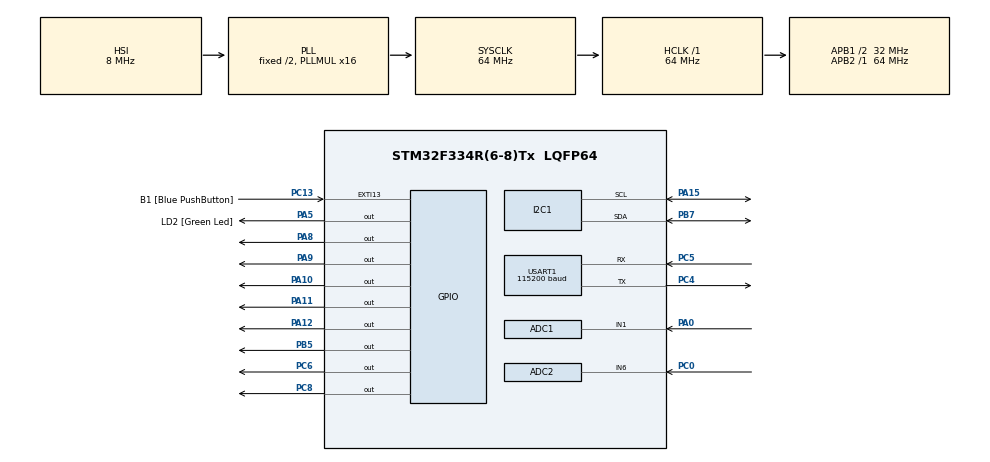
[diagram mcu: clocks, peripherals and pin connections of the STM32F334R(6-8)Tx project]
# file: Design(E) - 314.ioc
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ADC1.Channel-0\#ChannelRegularConversion=ADC_CHANNEL_1
ADC1.NbrOfConversionFlag=1
ADC1.Offset-0\#ChannelRegularConversion=0
ADC1.OffsetNumber-0\#ChannelRegularConversion=ADC_OFFSET_NONE
ADC1.Rank-0\#ChannelRegularConversion=1
ADC1.SamplingTime-0\#ChannelRegularConversion=ADC_SAMPLETIME_1CYCLE_5
ADC1.SubFamily=STM32F334x8
ADC1.master=1
ADC2.Channel-10\#ChannelRegularConversion=ADC_CHANNEL_6
ADC2.NbrOfConversionFlag=1
ADC2.Offset-10\#ChannelRegularConversion=0
ADC2.OffsetNumber-10\#ChannelRegularConversion=ADC_OFFSET_NONE
ADC2.Rank-10\#ChannelRegularConversion=1
ADC2.SamplingTime-10\#ChannelRegularConversion=ADC_SAMPLETIME_1CYCLE_5
ADC2.SubFamily=STM32F334x8
Mcu.Family=STM32F3
Mcu.Name=STM32F334R(6-8)Tx
Mcu.Package=LQFP64
NVIC.ADC1_2_IRQn=true\:0\:0\:false\:false\:true\:true\:true
NVIC.PriorityGroup=NVIC_PRIORITYGROUP_0
NVIC.USART1_IRQn=true\:0\:0\:false\:false\:true\:true\:true
PA0.Signal=SharedAnalog_PA0
PA10.Signal=GPIO_Output
PA11.Signal=GPIO_Output
PA12.Signal=GPIO_Output
PA13.GPIO_Label=TMS
PA13.Mode=Serial_Wire
PA13.Signal=SYS_JTMS-SWDIO
PA14.GPIO_Label=TCK
PA14.Mode=Serial_Wire
PA14.Signal=SYS_JTCK-SWCLK
PA15.Mode=I2C
PA15.Signal=I2C1_SCL
PA5.GPIO_Label=LD2 [Green Led]
PA5.Signal=GPIO_Output
PA8.Signal=GPIO_Output
PA9.Signal=GPIO_Output
PB3.GPIO_Label=SWO
PB3.Signal=SYS_JTDO-TRACESWO
PB5.Signal=GPIO_Output
PB7.Mode=I2C
PB7.Signal=I2C1_SDA
PC0.Signal=SharedAnalog_PC0
PC13.GPIO_Label=B1 [Blue PushButton]
PC13.GPIO_ModeDefaultEXTI=GPIO_MODE_IT_FALLING
PC13.Signal=GPXTI13
PC14\ /\ OSC32_IN.Mode=LSE-External-Oscillator
PC14\ /\ OSC32_IN.Signal=RCC_OSC32_IN
PC15\ /\ OSC32_OUT.GPIO_Label=RCC_OSC32_OUT
PC15\ /\ OSC32_OUT.Mode=LSE-External-Oscillator
PC15\ /\ OSC32_OUT.Signal=RCC_OSC32_OUT
PC4.Mode=Asynchronous
PC4.Signal=USART1_TX
PC5.Mode=Asynchronous
PC5.Signal=USART1_RX
PC6.Signal=GPIO_Output
PC8.Signal=GPIO_Output
PF0\ /\ OSC_IN.Mode=HSE-External-Clock-Source
PF0\ /\ OSC_IN.Signal=RCC_OSC_IN
PF1\ /\ OSC_OUT.Signal=RCC_OSC_OUT
ProjectManager.HeapSize=0x200
ProjectManager.StackSize=0x400
ProjectManager.TargetToolchain=TrueSTUDIO
RCC.AHBFreq_Value=64000000
RCC.APB1CLKDivider=RCC_HCLK_DIV2
RCC.APB1Freq_Value=32000000
RCC.APB1TimFreq_Value=64000000
RCC.APB2Freq_Value=64000000
RCC.APB2TimFreq_Value=64000000
RCC.CortexFreq_Value=64000000
RCC.FLatency-AdvancedSettings=FLASH_LATENCY_2
RCC.HCLKFreq_Value=64000000
RCC.HSE_VALUE=8000000
RCC.HSI_VALUE=8000000
RCC.PLLMUL=RCC_PLL_MUL16
RCC.SYSCLKFreq_VALUE=64000000
RCC.SYSCLKSourceVirtual=RCC_SYSCLKSOURCE_PLLCLK
SH.SharedAnalog_PA0.0=GPIO_Analog
SH.SharedAnalog_PA0.1=ADC1_IN1,IN1-Single-Ended
SH.SharedAnalog_PC0.0=GPIO_Analog
SH.SharedAnalog_PC0.1=ADC2_IN6,IN6-Single-Ended
USART1.BaudRate=115200
USART1.VirtualMode-Asynchronous=VM_ASYNC
board=NUCLEO-F334R8

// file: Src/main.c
/* USER CODE BEGIN Header */
/**
  ******************************************************************************
  * @file           : main.c
  * @brief          : Main program body
  ******************************************************************************
  ** This notice applies to any and all portions of this file
  * that are not between comment pairs USER CODE BEGIN and
  * USER CODE END. Other portions of this file, whether
  * inserted by the user or by software development tools
  * are owned by their respective copyright owners.
  *
  * COPYRIGHT(c) 2019 STMicroelectronics
  *
  * Redistribution and use in source and binary forms, with or without modification,
  * are permitted provided that the following conditions are met:
  *   1. Redistributions of source code must retain the above copyright notice,
  *      this list of conditions and the following disclaimer.
  *   2. Redistributions in binary form must reproduce the above copyright notice,
  *      this list of conditions and the following disclaimer in the documentation
  *      and/or other materials provided with the distribution.
  *   3. Neither the name of STMicroelectronics nor the names of its contributors
  *      may be used to endorse or promote products derived from this software
  *      without specific prior written permission.
  *
  * THIS SOFTWARE IS PROVIDED BY THE COPYRIGHT HOLDERS AND CONTRIBUTORS "AS IS"
  * AND ANY EXPRESS OR IMPLIED WARRANTIES, INCLUDING, BUT NOT LIMITED TO, THE
  * IMPLIED WARRANTIES OF MERCHANTABILITY AND FITNESS FOR A PARTICULAR PURPOSE ARE
  * DISCLAIMED. IN NO EVENT SHALL THE COPYRIGHT HOLDER OR CONTRIBUTORS BE LIABLE
  * FOR ANY DIRECT, INDIRECT, INCIDENTAL, SPECIAL, EXEMPLARY, OR CONSEQUENTIAL
  * DAMAGES (INCLUDING, BUT NOT LIMITED TO, PROCUREMENT OF SUBSTITUTE GOODS OR
  * SERVICES; LOSS OF USE, DATA, OR PROFITS; OR BUSINESS INTERRUPTION) HOWEVER
  * CAUSED AND ON ANY THEORY OF LIABILITY, WHETHER IN CONTRACT, STRICT LIABILITY,
  * OR TORT (INCLUDING NEGLIGENCE OR OTHERWISE) ARISING IN ANY WAY OUT OF THE USE
  * OF THIS SOFTWARE, EVEN IF ADVISED OF THE POSSIBILITY OF SUCH DAMAGE.
  *
  ******************************************************************************
  */
/* USER CODE END Header */

#include "main.h"

/* USER CODE BEGIN Includes */
#include "lcd.h"
#include "variables.h"
#include "project.h"
#include "bme280.h"
#include "bme280_defs.h"
#include "bme_sensor.h"
#include "lis2dh12_reg.h"
#include "accelerometer.h"

/* USER CODE END Includes */

void SystemClock_Config(void);
static void MX_GPIO_Init(void);
static void MX_USART1_UART_Init(void);
static void MX_ADC1_Init(void);
static void MX_ADC2_Init(void);
static void MX_I2C1_Init(void);

int main(void)
{

  /* MCU Configuration--------------------------------------------------------*/

  /* Reset of all peripherals, Initializes the Flash interface and the Systick. */
  HAL_Init();

  /* Configure the system clock */
  SystemClock_Config();

  /* Initialize all configured peripherals */
  MX_GPIO_Init();
  MX_USART1_UART_Init();
  MX_ADC1_Init();
  MX_ADC2_Init();
  MX_I2C1_Init();
  /* USER CODE BEGIN 2 */
  lcd_init();
  bme_init();
  stream_sensor_data_normal_mode(&dev);
  accelerometer_init();

  /* USER CODE END 2 */

  /* Infinite loop */
   while (1)
   {

    /* USER CODE BEGIN 3 */
	   HAL_UART_Receive_IT(&huart1,&inchar,1);
       initialise();
   }
  /* USER CODE END 3 */
}

void SystemClock_Config(void)
{
  RCC_OscInitTypeDef RCC_OscInitStruct = {0};
  RCC_ClkInitTypeDef RCC_ClkInitStruct = {0};
  RCC_PeriphCLKInitTypeDef PeriphClkInit = {0};

  /**Initializes the CPU, AHB and APB busses clocks
  */
  RCC_OscInitStruct.OscillatorType = RCC_OSCILLATORTYPE_HSI;
  RCC_OscInitStruct.HSIState = RCC_HSI_ON;
  RCC_OscInitStruct.HSICalibrationValue = RCC_HSICALIBRATION_DEFAULT;
  RCC_OscInitStruct.PLL.PLLState = RCC_PLL_ON;
  RCC_OscInitStruct.PLL.PLLSource = RCC_PLLSOURCE_HSI;
  RCC_OscInitStruct.PLL.PLLMUL = RCC_PLL_MUL16;
  if (HAL_RCC_OscConfig(&RCC_OscInitStruct) != HAL_OK)
  {
    Error_Handler();
  }
  /**Initializes the CPU, AHB and APB busses clocks
  */
  RCC_ClkInitStruct.ClockType = RCC_CLOCKTYPE_HCLK|RCC_CLOCKTYPE_SYSCLK
                              |RCC_CLOCKTYPE_PCLK1|RCC_CLOCKTYPE_PCLK2;
  RCC_ClkInitStruct.SYSCLKSource = RCC_SYSCLKSOURCE_PLLCLK;
  RCC_ClkInitStruct.AHBCLKDivider = RCC_SYSCLK_DIV1;
  RCC_ClkInitStruct.APB1CLKDivider = RCC_HCLK_DIV2;
  RCC_ClkInitStruct.APB2CLKDivider = RCC_HCLK_DIV1;

  if (HAL_RCC_ClockConfig(&RCC_ClkInitStruct, FLASH_LATENCY_2) != HAL_OK)
  {
    Error_Handler();
  }
  PeriphClkInit.PeriphClockSelection = RCC_PERIPHCLK_USART1|RCC_PERIPHCLK_I2C1
                              |RCC_PERIPHCLK_ADC12;
  PeriphClkInit.Usart1ClockSelection = RCC_USART1CLKSOURCE_PCLK1;
  PeriphClkInit.Adc12ClockSelection = RCC_ADC12PLLCLK_DIV1;
  PeriphClkInit.I2c1ClockSelection = RCC_I2C1CLKSOURCE_HSI;
  if (HAL_RCCEx_PeriphCLKConfig(&PeriphClkInit) != HAL_OK)
  {
    Error_Handler();
  }
}

static void MX_ADC1_Init(void)
{

  ADC_MultiModeTypeDef multimode = {0};
  ADC_ChannelConfTypeDef sConfig = {0};

  /**Common config
  */
  hadc1.Instance = ADC1;
  hadc1.Init.ClockPrescaler = ADC_CLOCK_ASYNC_DIV1;
  hadc1.Init.Resolution = ADC_RESOLUTION_12B;
  hadc1.Init.ScanConvMode = ADC_SCAN_DISABLE;
  hadc1.Init.ContinuousConvMode = DISABLE;
  hadc1.Init.DiscontinuousConvMode = DISABLE;
  hadc1.Init.ExternalTrigConvEdge = ADC_EXTERNALTRIGCONVEDGE_NONE;
  hadc1.Init.ExternalTrigConv = ADC_SOFTWARE_START;
  hadc1.Init.DataAlign = ADC_DATAALIGN_RIGHT;
  hadc1.Init.NbrOfConversion = 1;
  hadc1.Init.DMAContinuousRequests = DISABLE;
  hadc1.Init.EOCSelection = ADC_EOC_SINGLE_CONV;
  hadc1.Init.LowPowerAutoWait = DISABLE;
  hadc1.Init.Overrun = ADC_OVR_DATA_OVERWRITTEN;
  if (HAL_ADC_Init(&hadc1) != HAL_OK)
  {
    Error_Handler();
  }
  /**Configure the ADC multi-mode
  */
  multimode.Mode = ADC_MODE_INDEPENDENT;
  if (HAL_ADCEx_MultiModeConfigChannel(&hadc1, &multimode) != HAL_OK)
  {
    Error_Handler();
  }
  /**Configure Regular Channel
  */
  sConfig.Channel = ADC_CHANNEL_1;
  sConfig.Rank = ADC_REGULAR_RANK_1;
  sConfig.SingleDiff = ADC_SINGLE_ENDED;
  sConfig.SamplingTime = ADC_SAMPLETIME_1CYCLE_5;
  sConfig.OffsetNumber = ADC_OFFSET_NONE;
  sConfig.Offset = 0;
  if (HAL_ADC_ConfigChannel(&hadc1, &sConfig) != HAL_OK)
  {
    Error_Handler();
  }

}

static void MX_ADC2_Init(void)
{

  ADC_ChannelConfTypeDef sConfig = {0};

  /**Common config
  */
  hadc2.Instance = ADC2;
  hadc2.Init.ClockPrescaler = ADC_CLOCK_ASYNC_DIV1;
  hadc2.Init.Resolution = ADC_RESOLUTION_12B;
  hadc2.Init.ScanConvMode = ADC_SCAN_DISABLE;
  hadc2.Init.ContinuousConvMode = DISABLE;
  hadc2.Init.DiscontinuousConvMode = DISABLE;
  hadc2.Init.ExternalTrigConvEdge = ADC_EXTERNALTRIGCONVEDGE_NONE;
  hadc2.Init.ExternalTrigConv = ADC_SOFTWARE_START;
  hadc2.Init.DataAlign = ADC_DATAALIGN_RIGHT;
  hadc2.Init.NbrOfConversion = 1;
  hadc2.Init.DMAContinuousRequests = DISABLE;
  hadc2.Init.EOCSelection = ADC_EOC_SINGLE_CONV;
  hadc2.Init.LowPowerAutoWait = DISABLE;
  hadc2.Init.Overrun = ADC_OVR_DATA_OVERWRITTEN;
  if (HAL_ADC_Init(&hadc2) != HAL_OK)
  {
    Error_Handler();
  }
  /**Configure Regular Channel
  */
  sConfig.Channel = ADC_CHANNEL_6;
  sConfig.Rank = ADC_REGULAR_RANK_1;
  sConfig.SingleDiff = ADC_SINGLE_ENDED;
  sConfig.SamplingTime = ADC_SAMPLETIME_1CYCLE_5;
  sConfig.OffsetNumber = ADC_OFFSET_NONE;
  sConfig.Offset = 0;
  if (HAL_ADC_ConfigChannel(&hadc2, &sConfig) != HAL_OK)
  {
    Error_Handler();
  }

}

static void MX_I2C1_Init(void)
{

  hi2c1.Instance = I2C1;
  hi2c1.Init.Timing = 0x2000090E;
  hi2c1.Init.OwnAddress1 = 0;
  hi2c1.Init.AddressingMode = I2C_ADDRESSINGMODE_7BIT;
  hi2c1.Init.DualAddressMode = I2C_DUALADDRESS_DISABLE;
  hi2c1.Init.OwnAddress2 = 0;
  hi2c1.Init.OwnAddress2Masks = I2C_OA2_NOMASK;
  hi2c1.Init.GeneralCallMode = I2C_GENERALCALL_DISABLE;
  hi2c1.Init.NoStretchMode = I2C_NOSTRETCH_DISABLE;
  if (HAL_I2C_Init(&hi2c1) != HAL_OK)
  {
    Error_Handler();
  }
  /**Configure Analogue filter
  */
  if (HAL_I2CEx_ConfigAnalogFilter(&hi2c1, I2C_ANALOGFILTER_ENABLE) != HAL_OK)
  {
    Error_Handler();
  }
  /**Configure Digital filter
  */
  if (HAL_I2CEx_ConfigDigitalFilter(&hi2c1, 0) != HAL_OK)
  {
    Error_Handler();
  }

}

static void MX_USART1_UART_Init(void)
{

  huart1.Instance = USART1;
  huart1.Init.BaudRate = 115200;
  huart1.Init.WordLength = UART_WORDLENGTH_8B;
  huart1.Init.StopBits = UART_STOPBITS_1;
  huart1.Init.Parity = UART_PARITY_NONE;
  huart1.Init.Mode = UART_MODE_TX_RX;
  huart1.Init.HwFlowCtl = UART_HWCONTROL_NONE;
  huart1.Init.OverSampling = UART_OVERSAMPLING_16;
  huart1.Init.OneBitSampling = UART_ONE_BIT_SAMPLE_DISABLE;
  huart1.AdvancedInit.AdvFeatureInit = UART_ADVFEATURE_NO_INIT;
  if (HAL_UART_Init(&huart1) != HAL_OK)
  {
    Error_Handler();
  }

}

static void MX_GPIO_Init(void)
{
  GPIO_InitTypeDef GPIO_InitStruct = {0};

  /* GPIO Ports Clock Enable */
  __HAL_RCC_GPIOC_CLK_ENABLE();
  __HAL_RCC_GPIOF_CLK_ENABLE();
  __HAL_RCC_GPIOA_CLK_ENABLE();
  __HAL_RCC_GPIOB_CLK_ENABLE();

  /*Configure GPIO pin Output Level */
  HAL_GPIO_WritePin(GPIOA, LD2_Pin|GPIO_PIN_8|GPIO_PIN_9|GPIO_PIN_10
                          |GPIO_PIN_11|GPIO_PIN_12, GPIO_PIN_RESET);

  /*Configure GPIO pin Output Level */
  HAL_GPIO_WritePin(GPIOC, GPIO_PIN_6|GPIO_PIN_8, GPIO_PIN_RESET);

  /*Configure GPIO pin Output Level */
  HAL_GPIO_WritePin(GPIOB, GPIO_PIN_5, GPIO_PIN_RESET);

  /*Configure GPIO pin : B1_Pin */
  GPIO_InitStruct.Pin = B1_Pin;
  GPIO_InitStruct.Mode = GPIO_MODE_IT_FALLING;
  GPIO_InitStruct.Pull = GPIO_NOPULL;
  HAL_GPIO_Init(B1_GPIO_Port, &GPIO_InitStruct);

  /*Configure GPIO pin : PC0 */
  GPIO_InitStruct.Pin = GPIO_PIN_0;
  GPIO_InitStruct.Mode = GPIO_MODE_ANALOG;
  GPIO_InitStruct.Pull = GPIO_NOPULL;
  HAL_GPIO_Init(GPIOC, &GPIO_InitStruct);

  /*Configure GPIO pin : PA0 */
  GPIO_InitStruct.Pin = GPIO_PIN_0;
  GPIO_InitStruct.Mode = GPIO_MODE_ANALOG;
  GPIO_InitStruct.Pull = GPIO_NOPULL;
  HAL_GPIO_Init(GPIOA, &GPIO_InitStruct);

  /*Configure GPIO pins : LD2_Pin PA8 PA9 PA10
                           PA11 PA12 */
  GPIO_InitStruct.Pin = LD2_Pin|GPIO_PIN_8|GPIO_PIN_9|GPIO_PIN_10
                          |GPIO_PIN_11|GPIO_PIN_12;
  GPIO_InitStruct.Mode = GPIO_MODE_OUTPUT_PP;
  GPIO_InitStruct.Pull = GPIO_NOPULL;
  GPIO_InitStruct.Speed = GPIO_SPEED_FREQ_LOW;
  HAL_GPIO_Init(GPIOA, &GPIO_InitStruct);

  /*Configure GPIO pins : PC6 PC8 */
  GPIO_InitStruct.Pin = GPIO_PIN_6|GPIO_PIN_8;
  GPIO_InitStruct.Mode = GPIO_MODE_OUTPUT_PP;
  GPIO_InitStruct.Pull = GPIO_NOPULL;
  GPIO_InitStruct.Speed = GPIO_SPEED_FREQ_LOW;
  HAL_GPIO_Init(GPIOC, &GPIO_InitStruct);

  /*Configure GPIO pin : PB5 */
  GPIO_InitStruct.Pin = GPIO_PIN_5;
  GPIO_InitStruct.Mode = GPIO_MODE_OUTPUT_PP;
  GPIO_InitStruct.Pull = GPIO_NOPULL;
  GPIO_InitStruct.Speed = GPIO_SPEED_FREQ_LOW;
  HAL_GPIO_Init(GPIOB, &GPIO_InitStruct);

}

void Error_Handler(void)
{
}

/************************ (C) COPYRIGHT STMicroelectronics *****END OF FILE****/
